# cslr_sem register map
Vendor: Texas Instruments
Peripheral module from a debugger description file.
Registers are 32-bit, access per field, reset 0x0 unless marked. A register's access mark holds for its fields unless they carry their own. Offsets are as the file gives them; lines under a group give offsets from that group; [hi:lo] are bit positions; {n}, {i} and the like mark numbered series; 'fields as' and 'values as' point back to an identical list; <NAME> marks a mode.

## SEM — Semaphore perpheral
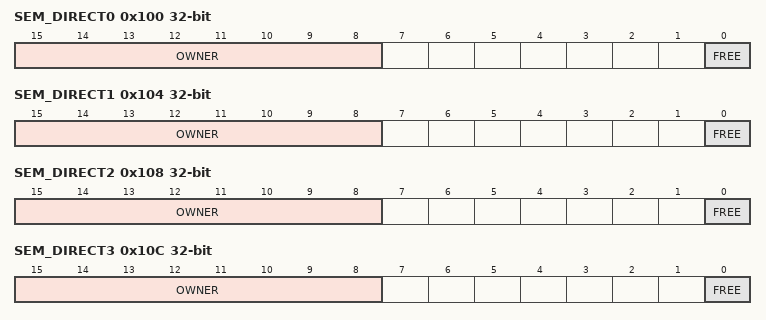
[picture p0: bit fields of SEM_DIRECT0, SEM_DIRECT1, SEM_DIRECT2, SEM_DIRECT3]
0x100 SEM_DIRECT0 — Semaphore Direct Access Register {SEM_DIR}
  [15:8] OWNER rw — Semaphore Owner
  [0] FREE rw — Free Status
    0=NOT_FREE; 1=FREE
0x104 SEM_DIRECT1 — Semaphore Direct Access Register {SEM_DIR}
  fields as SEM_DIRECT0
0x108 SEM_DIRECT2 — Semaphore Direct Access Register {SEM_DIR}
  fields as SEM_DIRECT0
0x10C SEM_DIRECT3 — Semaphore Direct Access Register {SEM_DIR}
  fields as SEM_DIRECT0
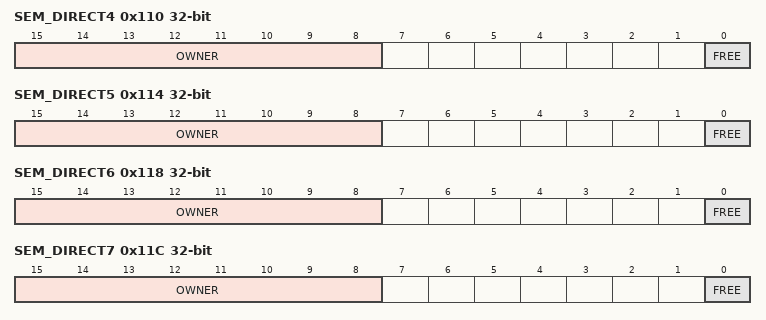
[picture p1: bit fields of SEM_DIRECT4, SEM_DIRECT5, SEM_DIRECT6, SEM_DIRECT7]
0x110 SEM_DIRECT4 — Semaphore Direct Access Register {SEM_DIR}
  fields as SEM_DIRECT0
0x114 SEM_DIRECT5 — Semaphore Direct Access Register {SEM_DIR}
  fields as SEM_DIRECT0
0x118 SEM_DIRECT6 — Semaphore Direct Access Register {SEM_DIR}
  fields as SEM_DIRECT0
0x11C SEM_DIRECT7 — Semaphore Direct Access Register {SEM_DIR}
  fields as SEM_DIRECT0
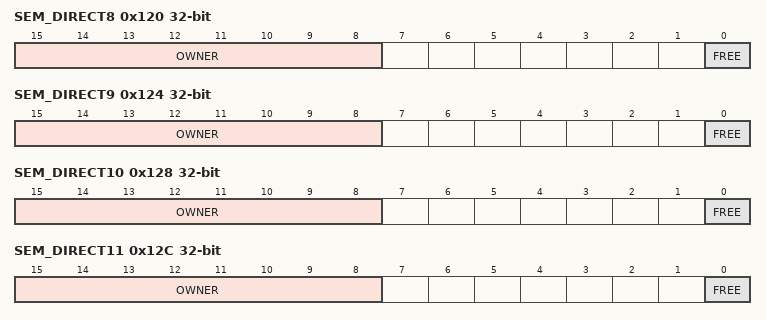
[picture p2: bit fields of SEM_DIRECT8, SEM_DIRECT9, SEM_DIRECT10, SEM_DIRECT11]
0x120 SEM_DIRECT8 — Semaphore Direct Access Register {SEM_DIR}
  fields as SEM_DIRECT0
0x124 SEM_DIRECT9 — Semaphore Direct Access Register {SEM_DIR}
  fields as SEM_DIRECT0
0x128 SEM_DIRECT10 — Semaphore Direct Access Register {SEM_DIR}
  fields as SEM_DIRECT0
0x12C SEM_DIRECT11 — Semaphore Direct Access Register {SEM_DIR}
  fields as SEM_DIRECT0
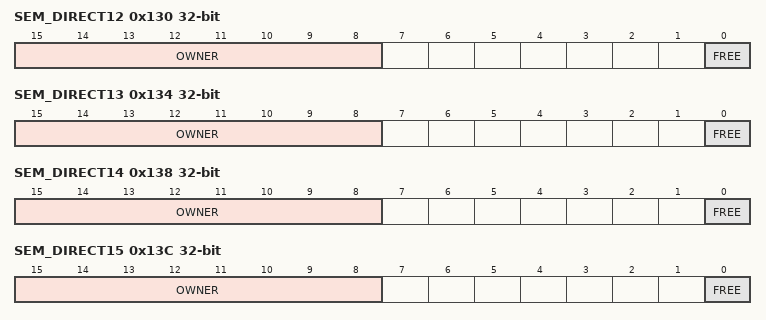
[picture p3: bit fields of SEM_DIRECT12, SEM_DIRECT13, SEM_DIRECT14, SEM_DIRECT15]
0x130 SEM_DIRECT12 — Semaphore Direct Access Register {SEM_DIR}
  fields as SEM_DIRECT0
0x134 SEM_DIRECT13 — Semaphore Direct Access Register {SEM_DIR}
  fields as SEM_DIRECT0
0x138 SEM_DIRECT14 — Semaphore Direct Access Register {SEM_DIR}
  fields as SEM_DIRECT0
0x13C SEM_DIRECT15 — Semaphore Direct Access Register {SEM_DIR}
  fields as SEM_DIRECT0
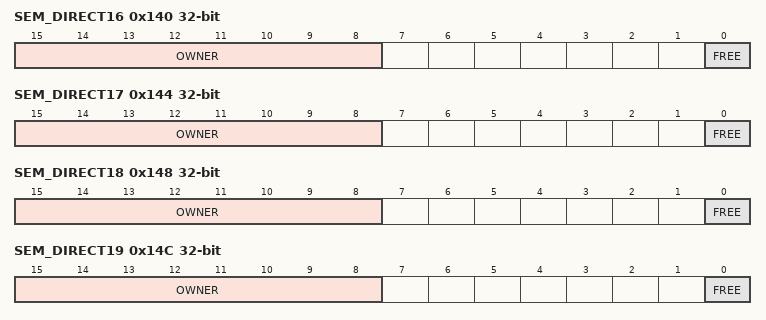
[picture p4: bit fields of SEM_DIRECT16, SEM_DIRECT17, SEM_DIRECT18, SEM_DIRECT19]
0x140 SEM_DIRECT16 — Semaphore Direct Access Register {SEM_DIR}
  fields as SEM_DIRECT0
0x144 SEM_DIRECT17 — Semaphore Direct Access Register {SEM_DIR}
  fields as SEM_DIRECT0
0x148 SEM_DIRECT18 — Semaphore Direct Access Register {SEM_DIR}
  fields as SEM_DIRECT0
0x14C SEM_DIRECT19 — Semaphore Direct Access Register {SEM_DIR}
  fields as SEM_DIRECT0
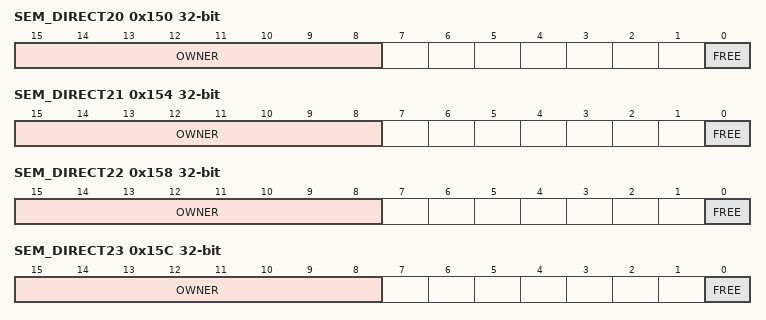
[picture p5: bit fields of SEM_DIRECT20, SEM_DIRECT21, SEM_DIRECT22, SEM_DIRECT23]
0x150 SEM_DIRECT20 — Semaphore Direct Access Register {SEM_DIR}
  fields as SEM_DIRECT0
0x154 SEM_DIRECT21 — Semaphore Direct Access Register {SEM_DIR}
  fields as SEM_DIRECT0
0x158 SEM_DIRECT22 — Semaphore Direct Access Register {SEM_DIR}
  fields as SEM_DIRECT0
0x15C SEM_DIRECT23 — Semaphore Direct Access Register {SEM_DIR}
  fields as SEM_DIRECT0
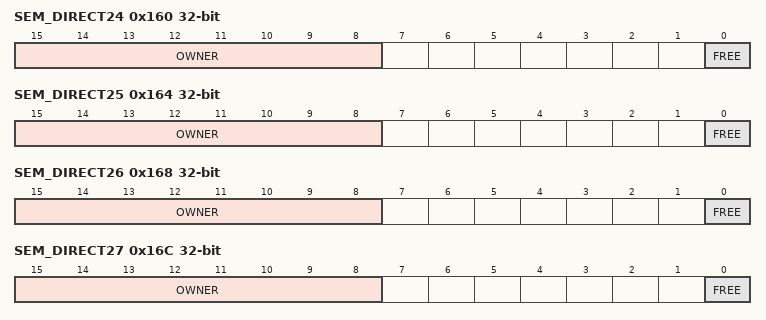
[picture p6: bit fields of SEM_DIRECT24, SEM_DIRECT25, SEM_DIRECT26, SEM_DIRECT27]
0x160 SEM_DIRECT24 — Semaphore Direct Access Register {SEM_DIR}
  fields as SEM_DIRECT0
0x164 SEM_DIRECT25 — Semaphore Direct Access Register {SEM_DIR}
  fields as SEM_DIRECT0
0x168 SEM_DIRECT26 — Semaphore Direct Access Register {SEM_DIR}
  fields as SEM_DIRECT0
0x16C SEM_DIRECT27 — Semaphore Direct Access Register {SEM_DIR}
  fields as SEM_DIRECT0
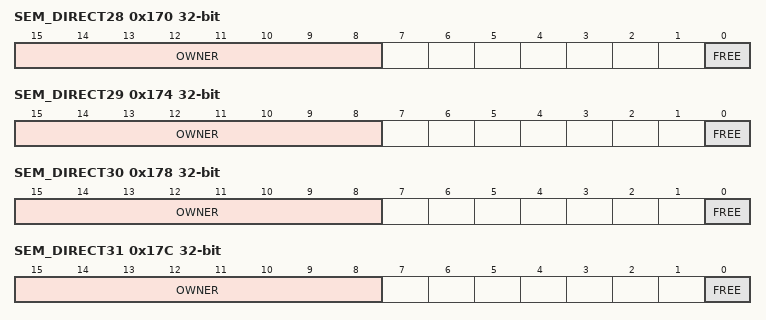
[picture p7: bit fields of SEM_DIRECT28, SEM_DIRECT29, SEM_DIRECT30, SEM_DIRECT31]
0x170 SEM_DIRECT28 — Semaphore Direct Access Register {SEM_DIR}
  fields as SEM_DIRECT0
0x174 SEM_DIRECT29 — Semaphore Direct Access Register {SEM_DIR}
  fields as SEM_DIRECT0
0x178 SEM_DIRECT30 — Semaphore Direct Access Register {SEM_DIR}
  fields as SEM_DIRECT0
0x17C SEM_DIRECT31 — Semaphore Direct Access Register {SEM_DIR}
  fields as SEM_DIRECT0
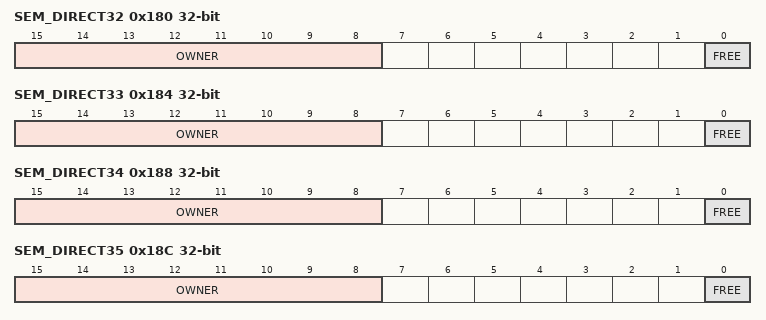
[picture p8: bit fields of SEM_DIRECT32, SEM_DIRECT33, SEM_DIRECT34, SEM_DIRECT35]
0x180 SEM_DIRECT32 — Semaphore Direct Access Register {SEM_DIR}
  fields as SEM_DIRECT0
0x184 SEM_DIRECT33 — Semaphore Direct Access Register {SEM_DIR}
  fields as SEM_DIRECT0
0x188 SEM_DIRECT34 — Semaphore Direct Access Register {SEM_DIR}
  fields as SEM_DIRECT0
0x18C SEM_DIRECT35 — Semaphore Direct Access Register {SEM_DIR}
  fields as SEM_DIRECT0
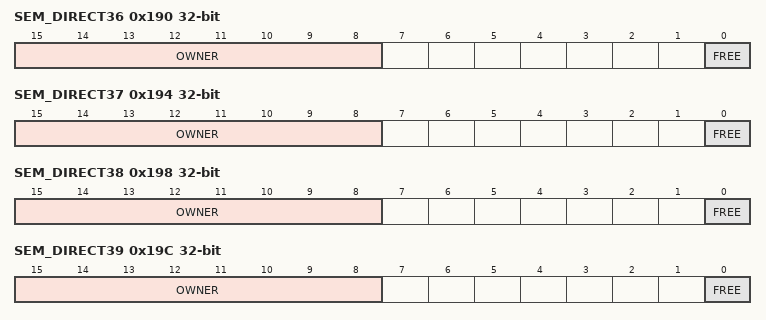
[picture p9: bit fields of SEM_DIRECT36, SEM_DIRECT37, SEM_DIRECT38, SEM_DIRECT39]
0x190 SEM_DIRECT36 — Semaphore Direct Access Register {SEM_DIR}
  fields as SEM_DIRECT0
0x194 SEM_DIRECT37 — Semaphore Direct Access Register {SEM_DIR}
  fields as SEM_DIRECT0
0x198 SEM_DIRECT38 — Semaphore Direct Access Register {SEM_DIR}
  fields as SEM_DIRECT0
0x19C SEM_DIRECT39 — Semaphore Direct Access Register {SEM_DIR}
  fields as SEM_DIRECT0
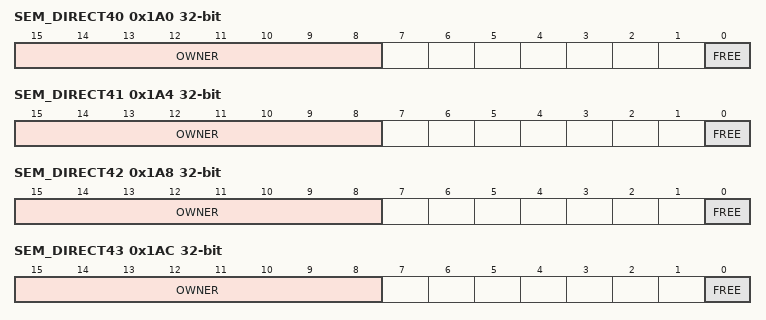
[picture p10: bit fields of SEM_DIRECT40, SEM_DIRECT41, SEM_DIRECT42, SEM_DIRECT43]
0x1A0 SEM_DIRECT40 — Semaphore Direct Access Register {SEM_DIR}
  fields as SEM_DIRECT0
0x1A4 SEM_DIRECT41 — Semaphore Direct Access Register {SEM_DIR}
  fields as SEM_DIRECT0
0x1A8 SEM_DIRECT42 — Semaphore Direct Access Register {SEM_DIR}
  fields as SEM_DIRECT0
0x1AC SEM_DIRECT43 — Semaphore Direct Access Register {SEM_DIR}
  fields as SEM_DIRECT0
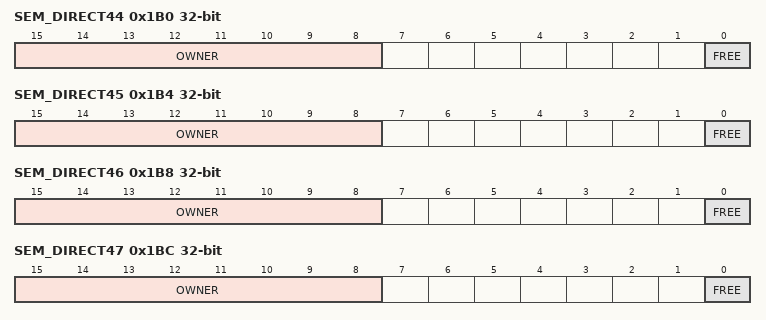
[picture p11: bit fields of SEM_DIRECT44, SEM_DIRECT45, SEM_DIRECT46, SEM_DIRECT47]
0x1B0 SEM_DIRECT44 — Semaphore Direct Access Register {SEM_DIR}
  fields as SEM_DIRECT0
0x1B4 SEM_DIRECT45 — Semaphore Direct Access Register {SEM_DIR}
  fields as SEM_DIRECT0
0x1B8 SEM_DIRECT46 — Semaphore Direct Access Register {SEM_DIR}
  fields as SEM_DIRECT0
0x1BC SEM_DIRECT47 — Semaphore Direct Access Register {SEM_DIR}
  fields as SEM_DIRECT0
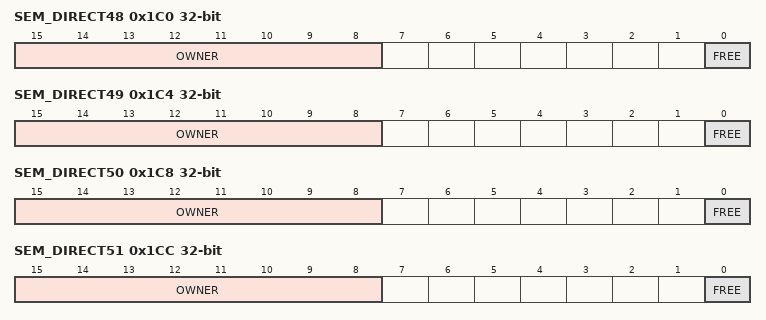
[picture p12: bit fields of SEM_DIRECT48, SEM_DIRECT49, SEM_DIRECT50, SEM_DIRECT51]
0x1C0 SEM_DIRECT48 — Semaphore Direct Access Register {SEM_DIR}
  fields as SEM_DIRECT0
0x1C4 SEM_DIRECT49 — Semaphore Direct Access Register {SEM_DIR}
  fields as SEM_DIRECT0
0x1C8 SEM_DIRECT50 — Semaphore Direct Access Register {SEM_DIR}
  fields as SEM_DIRECT0
0x1CC SEM_DIRECT51 — Semaphore Direct Access Register {SEM_DIR}
  fields as SEM_DIRECT0
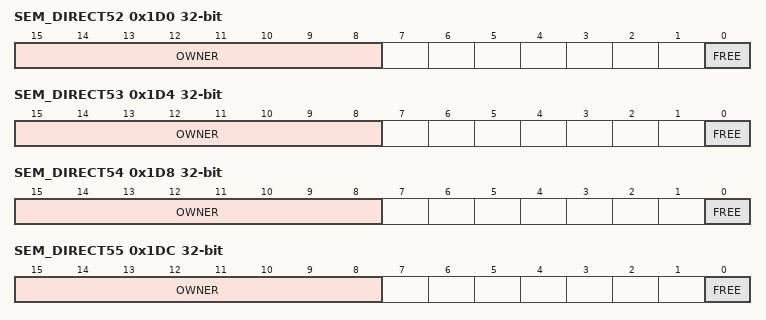
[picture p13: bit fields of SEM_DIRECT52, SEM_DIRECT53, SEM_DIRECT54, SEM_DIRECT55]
0x1D0 SEM_DIRECT52 — Semaphore Direct Access Register {SEM_DIR}
  fields as SEM_DIRECT0
0x1D4 SEM_DIRECT53 — Semaphore Direct Access Register {SEM_DIR}
  fields as SEM_DIRECT0
0x1D8 SEM_DIRECT54 — Semaphore Direct Access Register {SEM_DIR}
  fields as SEM_DIRECT0
0x1DC SEM_DIRECT55 — Semaphore Direct Access Register {SEM_DIR}
  fields as SEM_DIRECT0
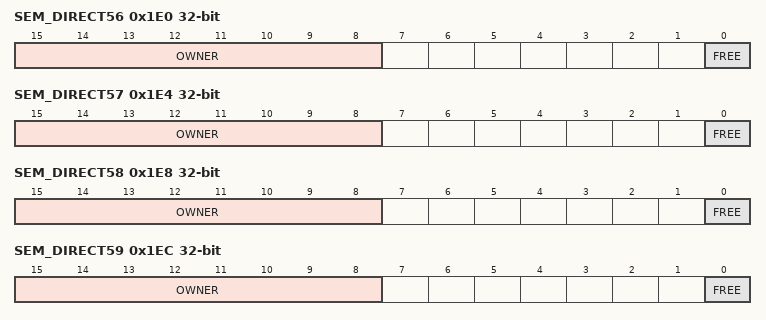
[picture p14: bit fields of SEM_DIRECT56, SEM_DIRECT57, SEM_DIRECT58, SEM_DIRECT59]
0x1E0 SEM_DIRECT56 — Semaphore Direct Access Register {SEM_DIR}
  fields as SEM_DIRECT0
0x1E4 SEM_DIRECT57 — Semaphore Direct Access Register {SEM_DIR}
  fields as SEM_DIRECT0
0x1E8 SEM_DIRECT58 — Semaphore Direct Access Register {SEM_DIR}
  fields as SEM_DIRECT0
0x1EC SEM_DIRECT59 — Semaphore Direct Access Register {SEM_DIR}
  fields as SEM_DIRECT0
0x1F0 SEM_DIRECT60 — Semaphore Direct Access Register {SEM_DIR}
  fields as SEM_DIRECT0
0x1F4 SEM_DIRECT61 — Semaphore Direct Access Register {SEM_DIR}
  fields as SEM_DIRECT0
0x1F8 SEM_DIRECT62 — Semaphore Direct Access Register {SEM_DIR}
  fields as SEM_DIRECT0
0x1FC SEM_DIRECT63 — Semaphore Direct Access Register {SEM_DIR}
  fields as SEM_DIRECT0
0x200 SEM_INDIRECT0 — Semaphore Indirect Access Register {SEM_IND}
  fields as SEM_DIRECT0
0x204 SEM_INDIRECT1 — Semaphore Indirect Access Register {SEM_IND}
  fields as SEM_DIRECT0
0x208 SEM_INDIRECT2 — Semaphore Indirect Access Register {SEM_IND}
  fields as SEM_DIRECT0
0x20C SEM_INDIRECT3 — Semaphore Indirect Access Register {SEM_IND}
  fields as SEM_DIRECT0
0x210 SEM_INDIRECT4 — Semaphore Indirect Access Register {SEM_IND}
  fields as SEM_DIRECT0
0x214 SEM_INDIRECT5 — Semaphore Indirect Access Register {SEM_IND}
  fields as SEM_DIRECT0
0x218 SEM_INDIRECT6 — Semaphore Indirect Access Register {SEM_IND}
  fields as SEM_DIRECT0
0x21C SEM_INDIRECT7 — Semaphore Indirect Access Register {SEM_IND}
  fields as SEM_DIRECT0
0x220 SEM_INDIRECT8 — Semaphore Indirect Access Register {SEM_IND}
  fields as SEM_DIRECT0
0x224 SEM_INDIRECT9 — Semaphore Indirect Access Register {SEM_IND}
  fields as SEM_DIRECT0
0x228 SEM_INDIRECT10 — Semaphore Indirect Access Register {SEM_IND}
  fields as SEM_DIRECT0
0x22C SEM_INDIRECT11 — Semaphore Indirect Access Register {SEM_IND}
  fields as SEM_DIRECT0
0x230 SEM_INDIRECT12 — Semaphore Indirect Access Register {SEM_IND}
  fields as SEM_DIRECT0
0x234 SEM_INDIRECT13 — Semaphore Indirect Access Register {SEM_IND}
  fields as SEM_DIRECT0
0x238 SEM_INDIRECT14 — Semaphore Indirect Access Register {SEM_IND}
  fields as SEM_DIRECT0
0x23C SEM_INDIRECT15 — Semaphore Indirect Access Register {SEM_IND}
  fields as SEM_DIRECT0
0x240 SEM_INDIRECT16 — Semaphore Indirect Access Register {SEM_IND}
  fields as SEM_DIRECT0
0x244 SEM_INDIRECT17 — Semaphore Indirect Access Register {SEM_IND}
  fields as SEM_DIRECT0
0x248 SEM_INDIRECT18 — Semaphore Indirect Access Register {SEM_IND}
  fields as SEM_DIRECT0
0x24C SEM_INDIRECT19 — Semaphore Indirect Access Register {SEM_IND}
  fields as SEM_DIRECT0
0x250 SEM_INDIRECT20 — Semaphore Indirect Access Register {SEM_IND}
  fields as SEM_DIRECT0
0x254 SEM_INDIRECT21 — Semaphore Indirect Access Register {SEM_IND}
  fields as SEM_DIRECT0
0x258 SEM_INDIRECT22 — Semaphore Indirect Access Register {SEM_IND}
  fields as SEM_DIRECT0
0x25C SEM_INDIRECT23 — Semaphore Indirect Access Register {SEM_IND}
  fields as SEM_DIRECT0
0x260 SEM_INDIRECT24 — Semaphore Indirect Access Register {SEM_IND}
  fields as SEM_DIRECT0
0x264 SEM_INDIRECT25 — Semaphore Indirect Access Register {SEM_IND}
  fields as SEM_DIRECT0
0x268 SEM_INDIRECT26 — Semaphore Indirect Access Register {SEM_IND}
  fields as SEM_DIRECT0
0x26C SEM_INDIRECT27 — Semaphore Indirect Access Register {SEM_IND}
  fields as SEM_DIRECT0
0x270 SEM_INDIRECT28 — Semaphore Indirect Access Register {SEM_IND}
  fields as SEM_DIRECT0
0x274 SEM_INDIRECT29 — Semaphore Indirect Access Register {SEM_IND}
  fields as SEM_DIRECT0
0x278 SEM_INDIRECT30 — Semaphore Indirect Access Register {SEM_IND}
  fields as SEM_DIRECT0
0x27C SEM_INDIRECT31 — Semaphore Indirect Access Register {SEM_IND}
  fields as SEM_DIRECT0
0x280 SEM_INDIRECT32 — Semaphore Indirect Access Register {SEM_IND}
  fields as SEM_DIRECT0
0x284 SEM_INDIRECT33 — Semaphore Indirect Access Register {SEM_IND}
  fields as SEM_DIRECT0
0x288 SEM_INDIRECT34 — Semaphore Indirect Access Register {SEM_IND}
  fields as SEM_DIRECT0
0x28C SEM_INDIRECT35 — Semaphore Indirect Access Register {SEM_IND}
  fields as SEM_DIRECT0
0x290 SEM_INDIRECT36 — Semaphore Indirect Access Register {SEM_IND}
  fields as SEM_DIRECT0
0x294 SEM_INDIRECT37 — Semaphore Indirect Access Register {SEM_IND}
  fields as SEM_DIRECT0
0x298 SEM_INDIRECT38 — Semaphore Indirect Access Register {SEM_IND}
  fields as SEM_DIRECT0
0x29C SEM_INDIRECT39 — Semaphore Indirect Access Register {SEM_IND}
  fields as SEM_DIRECT0
0x2A0 SEM_INDIRECT40 — Semaphore Indirect Access Register {SEM_IND}
  fields as SEM_DIRECT0
0x2A4 SEM_INDIRECT41 — Semaphore Indirect Access Register {SEM_IND}
  fields as SEM_DIRECT0
0x2A8 SEM_INDIRECT42 — Semaphore Indirect Access Register {SEM_IND}
  fields as SEM_DIRECT0
0x2AC SEM_INDIRECT43 — Semaphore Indirect Access Register {SEM_IND}
  fields as SEM_DIRECT0
0x2B0 SEM_INDIRECT44 — Semaphore Indirect Access Register {SEM_IND}
  fields as SEM_DIRECT0
0x2B4 SEM_INDIRECT45 — Semaphore Indirect Access Register {SEM_IND}
  fields as SEM_DIRECT0
0x2B8 SEM_INDIRECT46 — Semaphore Indirect Access Register {SEM_IND}
  fields as SEM_DIRECT0
0x2BC SEM_INDIRECT47 — Semaphore Indirect Access Register {SEM_IND}
  fields as SEM_DIRECT0
0x2C0 SEM_INDIRECT48 — Semaphore Indirect Access Register {SEM_IND}
  fields as SEM_DIRECT0
0x2C4 SEM_INDIRECT49 — Semaphore Indirect Access Register {SEM_IND}
  fields as SEM_DIRECT0
0x2C8 SEM_INDIRECT50 — Semaphore Indirect Access Register {SEM_IND}
  fields as SEM_DIRECT0
0x2CC SEM_INDIRECT51 — Semaphore Indirect Access Register {SEM_IND}
  fields as SEM_DIRECT0
0x2D0 SEM_INDIRECT52 — Semaphore Indirect Access Register {SEM_IND}
  fields as SEM_DIRECT0
0x2D4 SEM_INDIRECT53 — Semaphore Indirect Access Register {SEM_IND}
  fields as SEM_DIRECT0
0x2D8 SEM_INDIRECT54 — Semaphore Indirect Access Register {SEM_IND}
  fields as SEM_DIRECT0
0x2DC SEM_INDIRECT55 — Semaphore Indirect Access Register {SEM_IND}
  fields as SEM_DIRECT0
0x2E0 SEM_INDIRECT56 — Semaphore Indirect Access Register {SEM_IND}
  fields as SEM_DIRECT0
0x2E4 SEM_INDIRECT57 — Semaphore Indirect Access Register {SEM_IND}
  fields as SEM_DIRECT0
0x2E8 SEM_INDIRECT58 — Semaphore Indirect Access Register {SEM_IND}
  fields as SEM_DIRECT0
0x2EC SEM_INDIRECT59 — Semaphore Indirect Access Register {SEM_IND}
  fields as SEM_DIRECT0
0x2F0 SEM_INDIRECT60 — Semaphore Indirect Access Register {SEM_IND}
  fields as SEM_DIRECT0
0x2F4 SEM_INDIRECT61 — Semaphore Indirect Access Register {SEM_IND}
  fields as SEM_DIRECT0
0x2F8 SEM_INDIRECT62 — Semaphore Indirect Access Register {SEM_IND}
  fields as SEM_DIRECT0
0x2FC SEM_INDIRECT63 — Semaphore Indirect Access Register {SEM_IND}
  fields as SEM_DIRECT0
0x300 SEM_QUERY0 — Semaphore Query Register {SEM_QRY}
  fields as SEM_DIRECT0
0x304 SEM_QUERY1 — Semaphore Query Register {SEM_QRY}
  fields as SEM_DIRECT0
0x308 SEM_QUERY2 — Semaphore Query Register {SEM_QRY}
  fields as SEM_DIRECT0
0x30C SEM_QUERY3 — Semaphore Query Register {SEM_QRY}
  fields as SEM_DIRECT0
0x310 SEM_QUERY4 — Semaphore Query Register {SEM_QRY}
  fields as SEM_DIRECT0
0x314 SEM_QUERY5 — Semaphore Query Register {SEM_QRY}
  fields as SEM_DIRECT0
0x318 SEM_QUERY6 — Semaphore Query Register {SEM_QRY}
  fields as SEM_DIRECT0
0x31C SEM_QUERY7 — Semaphore Query Register {SEM_QRY}
  fields as SEM_DIRECT0
0x320 SEM_QUERY8 — Semaphore Query Register {SEM_QRY}
  fields as SEM_DIRECT0
0x324 SEM_QUERY9 — Semaphore Query Register {SEM_QRY}
  fields as SEM_DIRECT0
0x328 SEM_QUERY10 — Semaphore Query Register {SEM_QRY}
  fields as SEM_DIRECT0
0x32C SEM_QUERY11 — Semaphore Query Register {SEM_QRY}
  fields as SEM_DIRECT0
0x330 SEM_QUERY12 — Semaphore Query Register {SEM_QRY}
  fields as SEM_DIRECT0
0x334 SEM_QUERY13 — Semaphore Query Register {SEM_QRY}
  fields as SEM_DIRECT0
0x338 SEM_QUERY14 — Semaphore Query Register {SEM_QRY}
  fields as SEM_DIRECT0
0x33C SEM_QUERY15 — Semaphore Query Register {SEM_QRY}
  fields as SEM_DIRECT0
0x340 SEM_QUERY16 — Semaphore Query Register {SEM_QRY}
  fields as SEM_DIRECT0
0x344 SEM_QUERY17 — Semaphore Query Register {SEM_QRY}
  fields as SEM_DIRECT0
0x348 SEM_QUERY18 — Semaphore Query Register {SEM_QRY}
  fields as SEM_DIRECT0
0x34C SEM_QUERY19 — Semaphore Query Register {SEM_QRY}
  fields as SEM_DIRECT0
0x350 SEM_QUERY20 — Semaphore Query Register {SEM_QRY}
  fields as SEM_DIRECT0
0x354 SEM_QUERY21 — Semaphore Query Register {SEM_QRY}
  fields as SEM_DIRECT0
0x358 SEM_QUERY22 — Semaphore Query Register {SEM_QRY}
  fields as SEM_DIRECT0
0x35C SEM_QUERY23 — Semaphore Query Register {SEM_QRY}
  fields as SEM_DIRECT0
0x360 SEM_QUERY24 — Semaphore Query Register {SEM_QRY}
  fields as SEM_DIRECT0
0x364 SEM_QUERY25 — Semaphore Query Register {SEM_QRY}
  fields as SEM_DIRECT0
0x368 SEM_QUERY26 — Semaphore Query Register {SEM_QRY}
  fields as SEM_DIRECT0
0x36C SEM_QUERY27 — Semaphore Query Register {SEM_QRY}
  fields as SEM_DIRECT0
0x370 SEM_QUERY28 — Semaphore Query Register {SEM_QRY}
  fields as SEM_DIRECT0
0x374 SEM_QUERY29 — Semaphore Query Register {SEM_QRY}
  fields as SEM_DIRECT0
0x378 SEM_QUERY30 — Semaphore Query Register {SEM_QRY}
  fields as SEM_DIRECT0
0x37C SEM_QUERY31 — Semaphore Query Register {SEM_QRY}
  fields as SEM_DIRECT0
0x380 SEM_QUERY32 — Semaphore Query Register {SEM_QRY}
  fields as SEM_DIRECT0
0x384 SEM_QUERY33 — Semaphore Query Register {SEM_QRY}
  fields as SEM_DIRECT0
0x388 SEM_QUERY34 — Semaphore Query Register {SEM_QRY}
  fields as SEM_DIRECT0
0x38C SEM_QUERY35 — Semaphore Query Register {SEM_QRY}
  fields as SEM_DIRECT0
0x390 SEM_QUERY36 — Semaphore Query Register {SEM_QRY}
  fields as SEM_DIRECT0
0x394 SEM_QUERY37 — Semaphore Query Register {SEM_QRY}
  fields as SEM_DIRECT0
0x398 SEM_QUERY38 — Semaphore Query Register {SEM_QRY}
  fields as SEM_DIRECT0
0x39C SEM_QUERY39 — Semaphore Query Register {SEM_QRY}
  fields as SEM_DIRECT0
0x3A0 SEM_QUERY40 — Semaphore Query Register {SEM_QRY}
  fields as SEM_DIRECT0
0x3A4 SEM_QUERY41 — Semaphore Query Register {SEM_QRY}
  fields as SEM_DIRECT0
0x3A8 SEM_QUERY42 — Semaphore Query Register {SEM_QRY}
  fields as SEM_DIRECT0
0x3AC SEM_QUERY43 — Semaphore Query Register {SEM_QRY}
  fields as SEM_DIRECT0
0x3B0 SEM_QUERY44 — Semaphore Query Register {SEM_QRY}
  fields as SEM_DIRECT0
0x3B4 SEM_QUERY45 — Semaphore Query Register {SEM_QRY}
  fields as SEM_DIRECT0
0x3B8 SEM_QUERY46 — Semaphore Query Register {SEM_QRY}
  fields as SEM_DIRECT0
0x3BC SEM_QUERY47 — Semaphore Query Register {SEM_QRY}
  fields as SEM_DIRECT0
0x3C0 SEM_QUERY48 — Semaphore Query Register {SEM_QRY}
  fields as SEM_DIRECT0
0x3C4 SEM_QUERY49 — Semaphore Query Register {SEM_QRY}
  fields as SEM_DIRECT0
0x3C8 SEM_QUERY50 — Semaphore Query Register {SEM_QRY}
  fields as SEM_DIRECT0
0x3CC SEM_QUERY51 — Semaphore Query Register {SEM_QRY}
  fields as SEM_DIRECT0
0x3D0 SEM_QUERY52 — Semaphore Query Register {SEM_QRY}
  fields as SEM_DIRECT0
0x3D4 SEM_QUERY53 — Semaphore Query Register {SEM_QRY}
  fields as SEM_DIRECT0
0x3D8 SEM_QUERY54 — Semaphore Query Register {SEM_QRY}
  fields as SEM_DIRECT0
0x3DC SEM_QUERY55 — Semaphore Query Register {SEM_QRY}
  fields as SEM_DIRECT0
0x3E0 SEM_QUERY56 — Semaphore Query Register {SEM_QRY}
  fields as SEM_DIRECT0
0x3E4 SEM_QUERY57 — Semaphore Query Register {SEM_QRY}
  fields as SEM_DIRECT0
0x3E8 SEM_QUERY58 — Semaphore Query Register {SEM_QRY}
  fields as SEM_DIRECT0
0x3EC SEM_QUERY59 — Semaphore Query Register {SEM_QRY}
  fields as SEM_DIRECT0
0x3F0 SEM_QUERY60 — Semaphore Query Register {SEM_QRY}
  fields as SEM_DIRECT0
0x3F4 SEM_QUERY61 — Semaphore Query Register {SEM_QRY}
  fields as SEM_DIRECT0
0x3F8 SEM_QUERY62 — Semaphore Query Register {SEM_QRY}
  fields as SEM_DIRECT0
0x3FC SEM_QUERY63 — Semaphore Query Register {SEM_QRY}
  fields as SEM_DIRECT0
0x400 FLGL0 rw — Semaphore Flag Register Low {SEM_FLGL0}
  [all] fields
    0=NOT_OWNED; 1=OWNED
  [n] F{n} (n=0..31) — Ownership for semaphore {n}
0x404 FLGH0 rw — Semaphore Flag Register High {SEM_FLGH0}
  [all] fields
    0=NOT_OWNED; 1=OWNED
  [n-32] F{n} (n=32..63) — Ownership for semaphore {n}
0x408 FLGL1 rw — Semaphore Flag Register Low {SEM_FLGL1}
  fields as FLGL0
0x40C FLGH1 rw — Semaphore Flag Register High {SEM_FLGH1}
  fields as FLGH0
0x410 FLGL2 rw — Semaphore Flag Register Low {SEM_FLGL2}
  fields as FLGL0
0x414 FLGH2 rw — Semaphore Flag Register High {SEM_FLGH2}
  fields as FLGH0
0x418 FLGL3 rw — Semaphore Flag Register Low {SEM_FLGL3}
  fields as FLGL0
0x41C FLGH3 rw — Semaphore Flag Register High {SEM_FLGH3}
  fields as FLGH0
0x420 FLGL4 rw — Semaphore Flag Register Low {SEM_FLGL4}
  fields as FLGL0
0x424 FLGH4 rw — Semaphore Flag Register High {SEM_FLGH4}
  fields as FLGH0
0x428 FLGL5 rw — Semaphore Flag Register Low {SEM_FLGL5}
  fields as FLGL0
0x42C FLGH5 rw — Semaphore Flag Register High {SEM_FLGH5}
  fields as FLGH0
0x430 FLGL6 rw — Semaphore Flag Register Low {SEM_FLGL6}
  fields as FLGL0
0x434 FLGH6 rw — Semaphore Flag Register High {SEM_FLGH6}
  fields as FLGH0
0x438 FLGL7 rw — Semaphore Flag Register Low {SEM_FLGL7}
  fields as FLGL0
0x43C FLGH7 rw — Semaphore Flag Register High {SEM_FLGH7}
  fields as FLGH0
0x440 FLGL8 rw — Semaphore Flag Register Low {SEM_FLGL8}
  fields as FLGL0
0x444 FLGH8 rw — Semaphore Flag Register High {SEM_FLGH8}
  fields as FLGH0
0x448 FLGL9 rw — Semaphore Flag Register Low {SEM_FLGL9}
  fields as FLGL0
0x44C FLGH9 rw — Semaphore Flag Register High {SEM_FLGH9}
  fields as FLGH0
0x450 FLGL10 rw — Semaphore Flag Register Low {SEM_FLGL10}
  fields as FLGL0
0x454 FLGH10 rw — Semaphore Flag Register High {SEM_FLGH10}
  fields as FLGH0
0x458 FLGL11 rw — Semaphore Flag Register Low {SEM_FLGL11}
  fields as FLGL0
0x45C FLGH11 rw — Semaphore Flag Register High {SEM_FLGH11}
  fields as FLGH0
0x460 FLGL12 rw — Semaphore Flag Register Low {SEM_FLGL12}
  fields as FLGL0
0x464 FLGH12 rw — Semaphore Flag Register High {SEM_FLGH12}
  fields as FLGH0
0x468 FLGL13 rw — Semaphore Flag Register Low {SEM_FLGL13}
  fields as FLGL0
0x46C FLGH13 rw — Semaphore Flag Register High {SEM_FLGH13}
  fields as FLGH0
0x470 FLGL14 rw — Semaphore Flag Register Low {SEM_FLGL14}
  fields as FLGL0
0x474 FLGH14 rw — Semaphore Flag Register High {SEM_FLGH14}
  fields as FLGH0
0x478 FLGL15 rw — Semaphore Flag Register Low {SEM_FLGL15}
  fields as FLGL0
0x47C FLGH15 rw — Semaphore Flag Register High {SEM_FLGH15}
  fields as FLGH0
0x480 FLGL16 rw — Semaphore Flag Register Low {SEM_FLGL16}
  fields as FLGL0
0x484 FLGH16 rw — Semaphore Flag Register High {SEM_FLGH16}
  fields as FLGH0
0x488 FLGL17 rw — Semaphore Flag Register Low {SEM_FLGL17}
  fields as FLGL0
0x48C FLGH17 rw — Semaphore Flag Register High {SEM_FLGH17}
  fields as FLGH0
0x490 FLGL18 rw — Semaphore Flag Register Low {SEM_FLGL18}
  fields as FLGL0
0x494 FLGH18 rw — Semaphore Flag Register High {SEM_FLGH18}
  fields as FLGH0
0x498 FLGL19 rw — Semaphore Flag Register Low {SEM_FLGL19}
  fields as FLGL0
0x49C FLGH19 rw — Semaphore Flag Register High {SEM_FLGH19}
  fields as FLGH0
0x4A0 FLGL20 rw — Semaphore Flag Register Low {SEM_FLGL20}
  fields as FLGL0
0x4A4 FLGH20 rw — Semaphore Flag Register High {SEM_FLGH20}
  fields as FLGH0
0x4A8 FLGL21 rw — Semaphore Flag Register Low {SEM_FLGL21}
  fields as FLGL0
0x4AC FLGH21 rw — Semaphore Flag Register High {SEM_FLGH21}
  fields as FLGH0
0x4B0 FLGL22 rw — Semaphore Flag Register Low {SEM_FLGL22}
  fields as FLGL0
0x4B4 FLGH22 rw — Semaphore Flag Register High {SEM_FLGH22}
  fields as FLGH0
0x4B8 FLGL23 rw — Semaphore Flag Register Low {SEM_FLGL23}
  fields as FLGL0
0x4BC FLGH23 rw — Semaphore Flag Register High {SEM_FLGH23}
  fields as FLGH0
0x4C0 FLGL24 rw — Semaphore Flag Register Low {SEM_FLGL24}
  fields as FLGL0
0x4C4 FLGH24 rw — Semaphore Flag Register High {SEM_FLGH24}
  fields as FLGH0
0x4C8 FLGL25 rw — Semaphore Flag Register Low {SEM_FLGL25}
  fields as FLGL0
0x4CC FLGH25 rw — Semaphore Flag Register High {SEM_FLGH25}
  fields as FLGH0
0x4D0 FLGL26 rw — Semaphore Flag Register Low {SEM_FLGL26}
  fields as FLGL0
0x4D4 FLGH26 rw — Semaphore Flag Register High {SEM_FLGH26}
  fields as FLGH0
0x4D8 FLGL27 rw — Semaphore Flag Register Low {SEM_FLGL27}
  fields as FLGL0
0x4DC FLGH27 rw — Semaphore Flag Register High {SEM_FLGH27}
  fields as FLGH0
0x4E0 FLGL28 rw — Semaphore Flag Register Low {SEM_FLGL28}
  fields as FLGL0
0x4E4 FLGH28 rw — Semaphore Flag Register High {SEM_FLGH28}
  fields as FLGH0
0x4E8 FLGL29 rw — Semaphore Flag Register Low {SEM_FLGL29}
  fields as FLGL0
0x4EC FLGH29 rw — Semaphore Flag Register High {SEM_FLGH29}
  fields as FLGH0
0x4F0 FLGL30 rw — Semaphore Flag Register Low {SEM_FLGL30}
  fields as FLGL0
0x4F4 FLGH30 rw — Semaphore Flag Register High {SEM_FLGH30}
  fields as FLGH0
0x4F8 FLGL31 rw — Semaphore Flag Register Low {SEM_FLGL31}
  fields as FLGL0
0x4FC FLGH31 rw — Semaphore Flag Register High {SEM_FLGH31}
  fields as FLGH0
0x500 ERR0 ro — Error register {SEM_ERR0}
  [15:8] FAULTID — Faulting maser ID
  [6:2] SEMNUM — Semaphore number
  [1:0] ERROR — Error code
    0=NO_ERROR; 1=ALREADY_FREE; 2=BAD_OWNER; 3=REQ_PENDING
0x504 CLR0 — Error clear register {SEM_CLR0}
  [0] CLRERR wo — Clear error condition
    1=CLEAR_ERR
